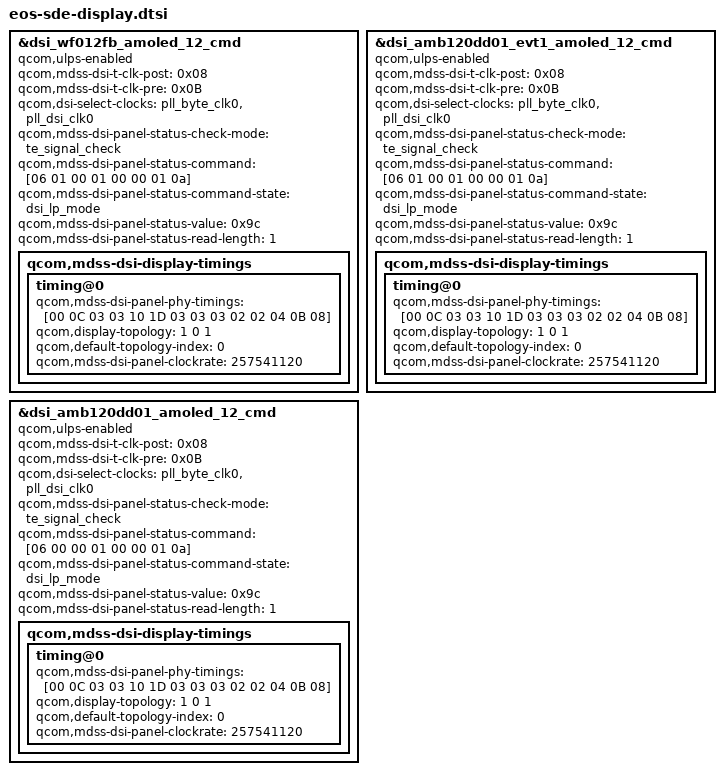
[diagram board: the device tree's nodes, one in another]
// SPDX-License-Identifier: GPL-2.0

#include <dt-bindings/clock/qcom,dispcc-monaco.h>
#include "dsi-panel-wf012fb-amoled-12-cmd.dtsi"
#include "dsi-panel-amb120dd01-evt1-amoled-12-cmd.dtsi"
#include "dsi-panel-amb120dd01-amoled-12-cmd.dtsi"

&dsi_wf012fb_amoled_12_cmd {
	qcom,ulps-enabled;
	qcom,mdss-dsi-t-clk-post = <0x08>;
	qcom,mdss-dsi-t-clk-pre = <0x0B>;
	qcom,dsi-select-clocks = "pll_byte_clk0", "pll_dsi_clk0";

	qcom,mdss-dsi-panel-status-check-mode = "te_signal_check";
	qcom,mdss-dsi-panel-status-command = [06 01 00 01 00 00 01 0a];
	qcom,mdss-dsi-panel-status-command-state = "dsi_lp_mode";
	qcom,mdss-dsi-panel-status-value = <0x9c>;
	qcom,mdss-dsi-panel-status-read-length = <1>;
	/*
	 * TODO: b/267644923: ESD te_signal_check is not supported anymore,
	 * so ESD checking is temporarily disabled.
	 */
	//qcom,esd-check-enabled;

	qcom,mdss-dsi-display-timings {
		timing@0 {
			qcom,mdss-dsi-panel-phy-timings = [00 0C 03 03 10 1D 03
				03 03 02 02 04 0B 08];
			qcom,display-topology = <1 0 1>;
			qcom,default-topology-index = <0>;
			qcom,mdss-dsi-panel-clockrate = <257541120>;
		};
	};
};

&dsi_amb120dd01_evt1_amoled_12_cmd {
	qcom,ulps-enabled;
	qcom,mdss-dsi-t-clk-post = <0x08>;
	qcom,mdss-dsi-t-clk-pre = <0x0B>;
	qcom,dsi-select-clocks = "pll_byte_clk0", "pll_dsi_clk0";

	qcom,mdss-dsi-panel-status-check-mode = "te_signal_check";
	qcom,mdss-dsi-panel-status-command = [06 01 00 01 00 00 01 0a];
	qcom,mdss-dsi-panel-status-command-state = "dsi_lp_mode";
	qcom,mdss-dsi-panel-status-value = <0x9c>;
	qcom,mdss-dsi-panel-status-read-length = <1>;
	/*
	 * TODO: b/267644923: ESD te_signal_check is not supported anymore,
	 * so ESD checking is temporarily disabled.
	 */
	//qcom,esd-check-enabled;

	qcom,mdss-dsi-display-timings {
		timing@0 {
			qcom,mdss-dsi-panel-phy-timings = [00 0C 03 03 10 1D 03
				03 03 02 02 04 0B 08];
			qcom,display-topology = <1 0 1>;
			qcom,default-topology-index = <0>;
			qcom,mdss-dsi-panel-clockrate = <257541120>;
		};
	};
};

&dsi_amb120dd01_amoled_12_cmd {
	qcom,ulps-enabled;
	qcom,mdss-dsi-t-clk-post = <0x08>;
	qcom,mdss-dsi-t-clk-pre = <0x0B>;
	qcom,dsi-select-clocks = "pll_byte_clk0", "pll_dsi_clk0";

	qcom,mdss-dsi-panel-status-check-mode = "te_signal_check";
	qcom,mdss-dsi-panel-status-command = [06 00 00 01 00 00 01 0a];
	qcom,mdss-dsi-panel-status-command-state = "dsi_lp_mode";
	qcom,mdss-dsi-panel-status-value = <0x9c>;
	qcom,mdss-dsi-panel-status-read-length = <1>;
	/*
	 * TODO: b/267644923: ESD te_signal_check is not supported anymore,
	 * so ESD checking is temporarily disabled.
	 */
	//qcom,esd-check-enabled;

	qcom,mdss-dsi-display-timings {
		timing@0 {
			qcom,mdss-dsi-panel-phy-timings = [00 0C 03 03 10 1D 03
				03 03 02 02 04 0B 08];
			qcom,display-topology = <1 0 1>;
			qcom,default-topology-index = <0>;
			qcom,mdss-dsi-panel-clockrate = <257541120>;
		};
	};
};
